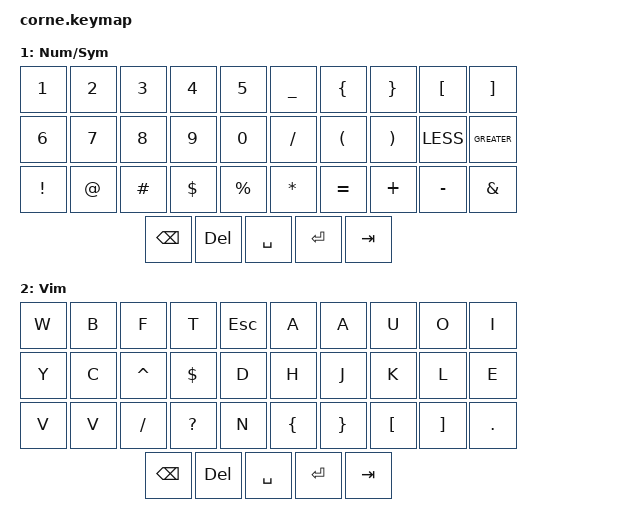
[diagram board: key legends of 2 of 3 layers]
/*
 * Copyright (c) 2020 The ZMK Contributors
 *
 * SPDX-License-Identifier: MIT
 */

#include <behaviors.dtsi>
#include <dt-bindings/zmk/keys.h>
#include <dt-bindings/zmk/bt.h>
#include <dt-bindings/zmk/pointing.h>


/ {
    chosen {
        zmk,physical-layout = &foostan_corne_5col_layout;
    };
    macros {
        not_equal: not_equal {
            compatible = "zmk,behavior-macro";
            #binding-cells = <0>;
            bindings = <&kp EXCL &kp EQUAL>;
        };
        fat_arrow: fat_arrow {
            compatible = "zmk,behavior-macro";
            #binding-cells = <0>;
            bindings = <&kp EQUAL &kp GREATER_THAN>;
        };
        arrow: arrow {
            compatible = "zmk,behavior-macro";
            #binding-cells = <0>;
            bindings = <&kp MINUS &kp GREATER_THAN>;
        };
        double_colon: double_colon {
            compatible = "zmk,behavior-macro";
            #binding-cells = <0>;
            bindings = <&kp COLON &kp COLON>;
        };
        logical_and: logical_and {
            compatible = "zmk,behavior-macro";
            #binding-cells = <0>;
            bindings = <&kp AMPS &kp AMPS>;
        };
        logical_or: logical_or {
            compatible = "zmk,behavior-macro";
            #binding-cells = <0>;
            bindings = <&kp PIPE &kp PIPE>;
        };
        vim_le: vim_le {
            compatible = "zmk,behavior-macro";
            #binding-cells = <0>;
            bindings = <&kp SEMI &kp G>;
        };
       vim_co: vim_co {
            compatible = "zmk,behavior-macro";
            #binding-cells = <0>;
            bindings = <&macro_tap &kp LCTRL &kp SLASH>;
        };
       cap_v: cap_v {
            compatible = "zmk,behavior-macro";
            #binding-cells = <0>;
            bindings = <&macro_tap &kp LSHFT &kp V>;
        };
    };

    behaviors {
        as: auto_shift {
            compatible = "zmk,behavior-hold-tap";
            #binding-cells = <2>;
            tapping-term-ms = <200>;
            quick-tap-ms = <0>;
            flavor = "tap-preferred";
            bindings = <&kp>, <&kp>;
        };

        lt: layer_tap {
            compatible = "zmk,behavior-hold-tap";
            #binding-cells = <2>;
            flavor = "tap-preferred"; // or "balanced", depending on desired behavior
            tapping-term-ms = <350>;
            quick-tap-ms = <350>;
            bindings = <&mo>, <&kp>; // mo for layer hold, kp for key tap
        };
        hml: homerow_mods_left {
            compatible = "zmk,behavior-hold-tap";
            #binding-cells = <2>;
            flavor = "balanced";
            tapping-term-ms = <280>;
            quick-tap-ms = <175>;
            require-prior-idle-ms = <150>;
            bindings = <&kp>, <&kp>;
            // hold-trigger-key-positions = <KEYS_R THUMBS>;
            hold-trigger-on-release;
        };
    
        hmr: homerow_mods_right {
            compatible = "zmk,behavior-hold-tap";
            #binding-cells = <2>;
            flavor = "balanced";
            tapping-term-ms = <280>;
            quick-tap-ms = <175>;
            require-prior-idle-ms = <150>;
            bindings = <&kp>, <&kp>;
            // hold-trigger-key-positions = <KEYS_L THUMBS>;
            hold-trigger-on-release;
        };
        lt: layer_tap { 
            compatible = "zmk,behavior-hold-tap"; 
            #binding-cells = <2>; flavor = "tap-preferred"; 
            tapping-term-ms = <300>; 
            quick-tap-ms = <300>;     
            bindings = <&mo>, <&kp>;     
        };
    };
    keymap {
        compatible = "zmk,keymap";
    
        default_layer {
            // 5-column Corne: 3 rows x 5 keys per hand (10 keys per row) + 3 thumb keys per hand
            // Layout: 
            // | W | G | D | F | B |     | Q | L | U | O | Y |
            // | R | S | T | H | K |     | J | N | E | A | I |
            // | X | C | M | P | V |     | Z | , | . | " | : |
          //   | RGUI | CTRL | SPC |     | BSPC | SHIFT | ENT |
            display-name = "Base";
            bindings = <
                &kp W &kp G &kp D &kp F &kp B           &kp Q &kp L &kp U &kp O &kp Y
                &kp R &kp S &lt 4 T &lt 2 H &kp K     &kp J &lt 3 N &lt 1 E &kp A &kp I
                &kp X &kp C &kp M &kp P &kp V           &kp Z &kp COMMA &kp DOT &kp DOUBLE_QUOTES &kp COLON
                  &kp GUI &kp LCTRL &lt 7 SPACE           &kp BSPC &sk LSHFT &kp ENTER
            >;
        };

        num_sym_layer {
            // Layout: Complete symbols for programming
            // | 1 | 2 | 3 | 4 | 5 |     | _ | { | } | [ | ] |
            // | 6 | 7 | 8 | 9 | 0 |     | / | ( | ) | < | > |
            // | ! | @ | # | $ | % |     | * | = | + | - | & |
            //       | NAN  | ALT |     | RGUI | SHIFT |   CTRL |
            display-name = "Num/Sym";
            bindings = <
                &kp N1 &kp N2 &kp N3 &kp N4 &kp N5     &kp UNDERSCORE &kp LBRC &kp RBRC &kp LEFT_BRACKET &kp RIGHT_BRACKET
                &kp N6 &kp N7 &kp N8 &kp N9 &kp N0     &kp SLASH &kp LPAR &kp RPAR &kp LESS &kp GREATER
                &kp EXCL &kp AT &kp HASH &kp DOLLAR &kp PERCENT     &kp STAR &kp EQUAL &kp PLUS &kp MINUS &kp AMPS
                  &kp BSPC &kp DEL           &kp SPACE &kp ENTER &kp TAB
            >;
        };

        vim_layer {
            // Layout: Comprehensive Vim for programming
            // | w | b | f | t | ESC |     | a | A | u | O | I |
            // | y | c | ^ | $ | d  |     | h | j | k | l | e |
            // | v | V | / | ? | n  |     | { | } | [ | ] | . |
            //         | NAN  | P   |      | NAN | NAN | NAN |
            display-name = "Vim";
            bindings = <
                &kp W &kp B &kp F &kp T &kp ESC           &kp A &kp A &kp U &kp O &kp I
                &kp Y &kp C &kp CARET &kp DOLLAR &kp D     &kp H &kp J &kp K &kp L &kp E
                &kp V &kp V &kp SLASH &kp QMARK &kp N     &kp LBRC &kp RBRC &kp LEFT_BRACKET &kp RIGHT_BRACKET &kp DOT
                  &kp BSPC &kp DEL           &kp SPACE &kp ENTER &kp TAB
            >;
        };
    };
};
